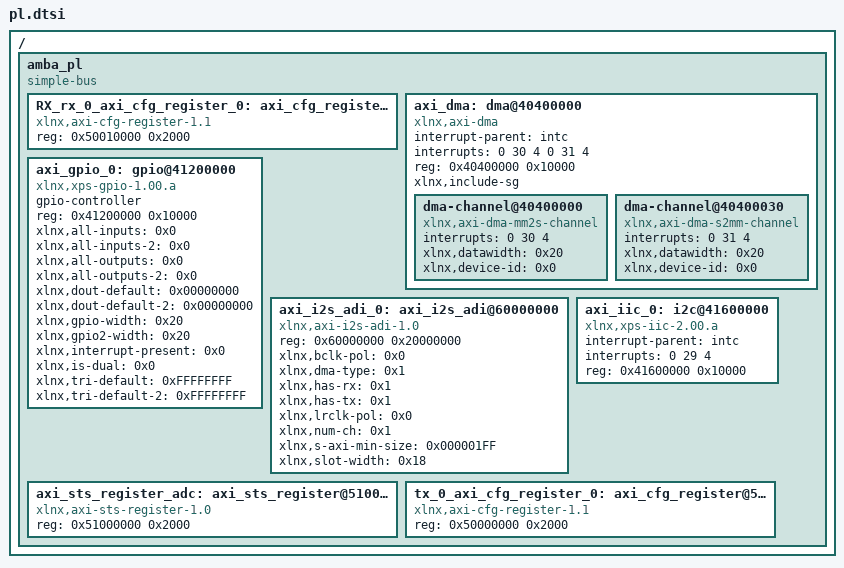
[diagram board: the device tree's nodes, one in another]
/*
 * CAUTION: This file is automatically generated by Xilinx.
 * Version: HSI 2015.2
 * Today is: Tue Nov  3 16:13:31 2015
*/


/ {
	amba_pl: amba_pl {
		#address-cells = <1>;
		#size-cells = <1>;
		compatible = "simple-bus";
		ranges ;
		RX_rx_0_axi_cfg_register_0: axi_cfg_register@50010000 {
			compatible = "xlnx,axi-cfg-register-1.1";
			reg = <0x50010000 0x2000>;
		};
		axi_dma: dma@40400000 {
			compatible = "xlnx,axi-dma";
			interrupt-parent = <&intc>;
			interrupts = <0 30 4 0 31 4>;
			reg = <0x40400000 0x10000>;
			xlnx,include-sg ;
			dma-channel@40400000 {
				compatible = "xlnx,axi-dma-mm2s-channel";
				interrupts = <0 30 4>;
				xlnx,datawidth = <0x20>;
				xlnx,device-id = <0x0>;
			};
			dma-channel@40400030 {
				compatible = "xlnx,axi-dma-s2mm-channel";
				interrupts = <0 31 4>;
				xlnx,datawidth = <0x20>;
				xlnx,device-id = <0x0>;
			};
		};
		axi_gpio_0: gpio@41200000 {
			#gpio-cells = <2>;
			compatible = "xlnx,xps-gpio-1.00.a";
			gpio-controller ;
			reg = <0x41200000 0x10000>;
			xlnx,all-inputs = <0x0>;
			xlnx,all-inputs-2 = <0x0>;
			xlnx,all-outputs = <0x0>;
			xlnx,all-outputs-2 = <0x0>;
			xlnx,dout-default = <0x00000000>;
			xlnx,dout-default-2 = <0x00000000>;
			xlnx,gpio-width = <0x20>;
			xlnx,gpio2-width = <0x20>;
			xlnx,interrupt-present = <0x0>;
			xlnx,is-dual = <0x0>;
			xlnx,tri-default = <0xFFFFFFFF>;
			xlnx,tri-default-2 = <0xFFFFFFFF>;
		};
		axi_i2s_adi_0: axi_i2s_adi@60000000 {
			compatible = "xlnx,axi-i2s-adi-1.0";
			reg = <0x60000000 0x20000000>;
			xlnx,bclk-pol = <0x0>;
			xlnx,dma-type = <0x1>;
			xlnx,has-rx = <0x1>;
			xlnx,has-tx = <0x1>;
			xlnx,lrclk-pol = <0x0>;
			xlnx,num-ch = <0x1>;
			xlnx,s-axi-min-size = <0x000001FF>;
			xlnx,slot-width = <0x18>;
		};
		axi_iic_0: i2c@41600000 {
			#address-cells = <1>;
			#size-cells = <0>;
			compatible = "xlnx,xps-iic-2.00.a";
			interrupt-parent = <&intc>;
			interrupts = <0 29 4>;
			reg = <0x41600000 0x10000>;
		};
		axi_sts_register_adc: axi_sts_register@51000000 {
			compatible = "xlnx,axi-sts-register-1.0";
			reg = <0x51000000 0x2000>;
		};
		tx_0_axi_cfg_register_0: axi_cfg_register@50000000 {
			compatible = "xlnx,axi-cfg-register-1.1";
			reg = <0x50000000 0x2000>;
		};
	};
};
